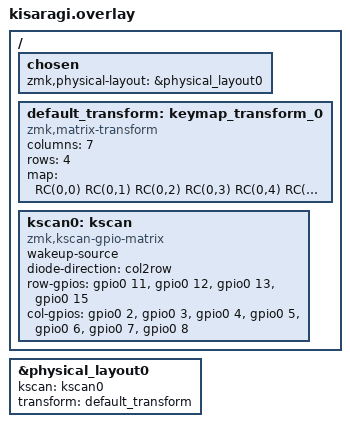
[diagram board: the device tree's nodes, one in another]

#include <dt-bindings/zmk/matrix_transform.h>
#include "layouts.dtsi"

/ {
    chosen {
        zmk,physical-layout = &physical_layout0;
    };

    default_transform: keymap_transform_0 {
        compatible = "zmk,matrix-transform";
        columns = <7>;
        rows = <4>;
        map = <
            RC(0,0) RC(0,1) RC(0,2) RC(0,3) RC(0,4) RC(0,5) RC(0,6) RC(1,0) RC(1,1) RC(1,2) RC(1,3) RC(1,4) RC(1,5) RC(1,6) RC(2,0) RC(2,1) RC(2,2) RC(2,3) RC(2,4) RC(2,5) RC(2,6) RC(3,0) RC(3,1) RC(3,2) RC(3,3) RC(3,4) RC(3,5) RC(3,6)
        >;
    };

    kscan0: kscan {
        compatible = "zmk,kscan-gpio-matrix";
        wakeup-source;

        diode-direction = "col2row";
        row-gpios
            = <&gpio0 11 (GPIO_ACTIVE_HIGH | GPIO_PULL_DOWN)>
			, <&gpio0 12 (GPIO_ACTIVE_HIGH | GPIO_PULL_DOWN)>
			, <&gpio0 13 (GPIO_ACTIVE_HIGH | GPIO_PULL_DOWN)>
			, <&gpio0 15 (GPIO_ACTIVE_HIGH | GPIO_PULL_DOWN)>
            ;
        col-gpios
            = <&gpio0 2 GPIO_ACTIVE_HIGH>
			, <&gpio0 3 GPIO_ACTIVE_HIGH>
			, <&gpio0 4 GPIO_ACTIVE_HIGH>
			, <&gpio0 5 GPIO_ACTIVE_HIGH>
			, <&gpio0 6 GPIO_ACTIVE_HIGH>
			, <&gpio0 7 GPIO_ACTIVE_HIGH>
			, <&gpio0 8 GPIO_ACTIVE_HIGH>
            ;
    };


};

&physical_layout0 {
    kscan = <&kscan0>;
    transform = <&default_transform>;
};
